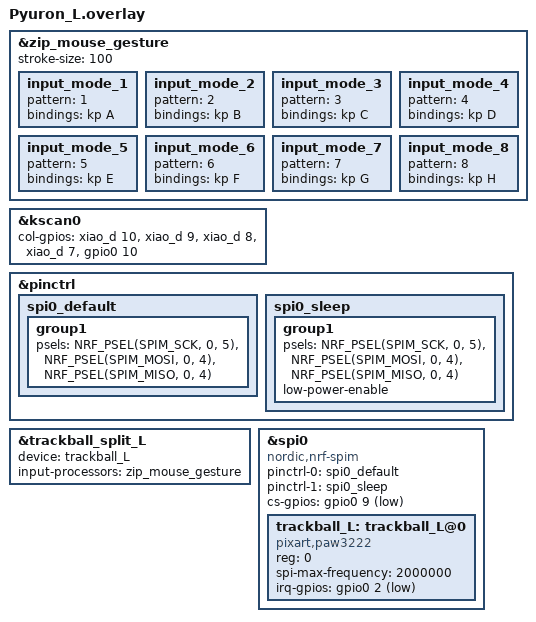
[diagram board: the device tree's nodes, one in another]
#include <zephyr/dt-bindings/input/input-event-codes.h>
#include <dt-bindings/zmk/input_transform.h>
#include <input/processors.dtsi>
#include <dt-bindings/zmk/bt.h>
#include "Pyuron.dtsi"
#include <mouse-gesture.dtsi>

/* あなたの環境の実測値に基づく独自定義 gestuer_mouse用 */
#define MG_UP    1
#define MG_DOWN  2
#define MG_RIGHT 8
#define MG_LEFT  4

/* ジェスチャー定義 */
&zip_mouse_gesture {
    stroke-size = <100>;
    input_mode_1 {
        pattern = <1>;
        bindings = <&kp A>;
    };
    input_mode_2 {
        pattern = <2>;
        bindings = <&kp B>;
    };
    input_mode_3 {
        pattern = <3>;
        bindings = <&kp C>;
    };
    input_mode_4 {
        pattern = <4>;
        bindings = <&kp D>;
    };
    input_mode_5 {
        pattern = <5>;
        bindings = <&kp E>;
    };
    input_mode_6 {
        pattern = <6>;
        bindings = <&kp F>;
    };
    input_mode_7 {
        pattern = <7>;
        bindings = <&kp G>;
    };
    input_mode_8 {
        pattern = <8>;
        bindings = <&kp H>;
    };

};


&kscan0 {
        col-gpios
            = <&xiao_d 10 GPIO_ACTIVE_HIGH>
            , <&xiao_d 9 GPIO_ACTIVE_HIGH> 
            , <&xiao_d 8 GPIO_ACTIVE_HIGH> 
            , <&xiao_d 7 GPIO_ACTIVE_HIGH> 
            , <&gpio0 10 GPIO_ACTIVE_HIGH>
            ;
};

&pinctrl {
    spi0_default: spi0_default {
        group1 {
            psels = <NRF_PSEL(SPIM_SCK, 0, 5)>,
                    <NRF_PSEL(SPIM_MOSI, 0, 4)>,
                    <NRF_PSEL(SPIM_MISO, 0, 4)>;
        };
    };

    spi0_sleep: spi0_sleep {
        group1 {
            psels = <NRF_PSEL(SPIM_SCK, 0, 5)>,
                    <NRF_PSEL(SPIM_MOSI, 0, 4)>,
                    <NRF_PSEL(SPIM_MISO, 0, 4)>;
            low-power-enable;
        };
    };
};

&trackball_split_L {
    device = <&trackball_L>;
    input-processors = <&zip_mouse_gesture>;
};

&spi0 {
    status = "okay";
    compatible = "nordic,nrf-spim";
    pinctrl-0 = <&spi0_default>;
    pinctrl-1 = <&spi0_sleep>;
    pinctrl-names = "default", "sleep";
    cs-gpios = <&gpio0 9 GPIO_ACTIVE_LOW>;

    trackball_L: trackball_L@0 {
        status = "okay";
        compatible = "pixart,paw3222";
        reg = <0>;
        spi-max-frequency = <2000000>;
        irq-gpios = <&gpio0 2 (GPIO_ACTIVE_LOW | GPIO_PULL_UP)>;
    };
};
